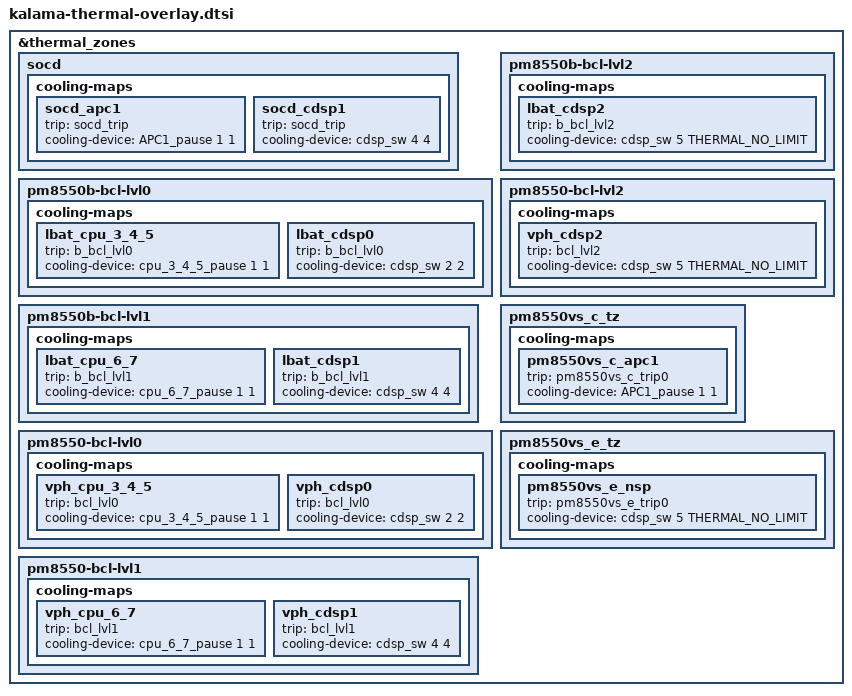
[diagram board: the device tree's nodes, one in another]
#include <dt-bindings/thermal/thermal_qti.h>

&thermal_zones {
	socd {
		cooling-maps {
			socd_apc1 {
				trip = <&socd_trip>;
				cooling-device = <&APC1_pause 1 1>;
			};

			socd_cdsp1 {
				trip = <&socd_trip>;
				cooling-device = <&cdsp_sw 4 4>;
			};
		};
	};

	pm8550b-bcl-lvl0 {
		cooling-maps {
			lbat_cpu_3_4_5 {
				trip = <&b_bcl_lvl0>;
				cooling-device = <&cpu_3_4_5_pause 1 1>;
			};

			lbat_cdsp0 {
				trip = <&b_bcl_lvl0>;
				cooling-device = <&cdsp_sw 2 2>;
			};
		};
	};

	pm8550b-bcl-lvl1 {
		cooling-maps {
			lbat_cpu_6_7 {
				trip = <&b_bcl_lvl1>;
				cooling-device = <&cpu_6_7_pause 1 1>;
			};

			lbat_cdsp1 {
				trip = <&b_bcl_lvl1>;
				cooling-device = <&cdsp_sw 4 4>;
			};
		};
	};

	pm8550b-bcl-lvl2 {
		cooling-maps {
			lbat_cdsp2 {
				trip = <&b_bcl_lvl2>;
				cooling-device = <&cdsp_sw 5 THERMAL_NO_LIMIT>;
			};
		};
	};

	pm8550-bcl-lvl0 {
		cooling-maps {
			vph_cpu_3_4_5 {
				trip = <&bcl_lvl0>;
				cooling-device = <&cpu_3_4_5_pause 1 1>;
			};

			vph_cdsp0 {
				trip = <&bcl_lvl0>;
				cooling-device = <&cdsp_sw 2 2>;
			};
		};
	};

	pm8550-bcl-lvl1 {
		cooling-maps {
			vph_cpu_6_7 {
				trip = <&bcl_lvl1>;
				cooling-device = <&cpu_6_7_pause 1 1>;
			};

			vph_cdsp1 {
				trip = <&bcl_lvl1>;
				cooling-device = <&cdsp_sw 4 4>;
			};
		};
	};

	pm8550-bcl-lvl2 {
		cooling-maps {
			vph_cdsp2 {
				trip = <&bcl_lvl2>;
				cooling-device = <&cdsp_sw 5 THERMAL_NO_LIMIT>;
			};
		};
	};

	pm8550vs_c_tz {
		cooling-maps {
			pm8550vs_c_apc1 {
				trip = <&pm8550vs_c_trip0>;
				cooling-device = <&APC1_pause 1 1>;
			};
		};
	};

	pm8550vs_e_tz {
		cooling-maps {
			pm8550vs_e_nsp {
				trip = <&pm8550vs_e_trip0>;
				cooling-device = <&cdsp_sw 5 THERMAL_NO_LIMIT>;
			};
		};
	};
};
